AUTOSAR XML (schema 00051)
package /Components
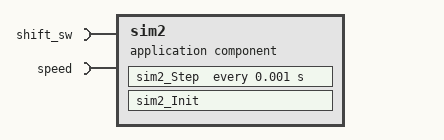
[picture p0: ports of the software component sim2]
  application sw component type sim2
    require port shift_sw: nonqueued-receiver-com-spec{data-element=shift_sw, init-value=0}, required-interface=shift_sw
    require port speed: nonqueued-receiver-com-spec{data-element=speed, init-value=0}, required-interface=speed
    behavior sim2_IB: handle-termination-and-restart=NO-SUPPORT
      timing event Event_sim2_Step: start-on-event=sim2_Step, period=0.001
      runnable sim2_Init
      runnable sim2_Step
        data-read-access:
          access IN_shift_sw_shift_sw: accessed-variable=shift_sw.shift_sw
          access IN_speed_speed: accessed-variable=speed.speed
